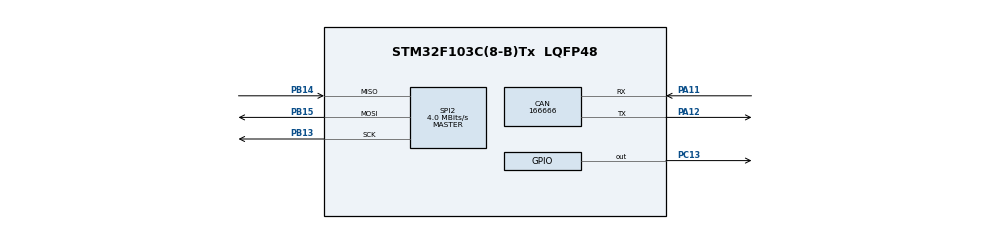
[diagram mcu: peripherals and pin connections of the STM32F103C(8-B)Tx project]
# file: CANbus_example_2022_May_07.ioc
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CAN.CalculateBaudRate=166666
CAN.CalculateTimeBit=6000
CAN.CalculateTimeQuantum=2000.0
Mcu.Family=STM32F1
Mcu.Name=STM32F103C(8-B)Tx
Mcu.Package=LQFP48
NVIC.PriorityGroup=NVIC_PRIORITYGROUP_4
PA11.Mode=CAN_Activate
PA11.Signal=CAN_RX
PA12.Mode=CAN_Activate
PA12.Signal=CAN_TX
PA13.Mode=Serial_Wire
PA13.Signal=SYS_JTMS-SWDIO
PA14.Mode=Serial_Wire
PA14.Signal=SYS_JTCK-SWCLK
PB13.Mode=Full_Duplex_Master
PB13.Signal=SPI2_SCK
PB14.Mode=Full_Duplex_Master
PB14.Signal=SPI2_MISO
PB15.Mode=Full_Duplex_Master
PB15.Signal=SPI2_MOSI
PC13-TAMPER-RTC.Signal=GPIO_Output
ProjectManager.HeapSize=0x200
ProjectManager.StackSize=0x400
ProjectManager.TargetToolchain=STM32CubeIDE
RCC.APB1Freq_Value=8000000
RCC.APB2Freq_Value=8000000
SPI2.CalculateBaudRate=4.0 MBits/s
SPI2.Direction=SPI_DIRECTION_2LINES
SPI2.Mode=SPI_MODE_MASTER
SPI2.VirtualType=VM_MASTER
board=custom

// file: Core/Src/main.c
/* USER CODE BEGIN Header */
/**
  ******************************************************************************
  * @file           : main.c
  * @brief          : Main program body
  ******************************************************************************
  * @attention
  *
  * Copyright (c) 2022 STMicroelectronics.
  * All rights reserved.
  *
  * This software is licensed under terms that can be found in the LICENSE file
  * in the root directory of this software component.
  * If no LICENSE file comes with this software, it is provided AS-IS.
  *
  ******************************************************************************
  */
/* USER CODE END Header */
#include "main.h"

/* USER CODE BEGIN Includes */
#include "BLINKY_bluepill.h"
#include "CANbus_functions.h"

/* USER CODE END Includes */

 CAN_HandleTypeDef hcan;

SPI_HandleTypeDef hspi2;

void SystemClock_Config(void);
static void MX_GPIO_Init(void);
static void MX_CAN_Init(void);
static void MX_SPI2_Init(void);

int main(void)
{
  /* USER CODE BEGIN 1 */
	Brightside_CAN_MessageSeries* pSeries;
  /* USER CODE END 1 */

  /* MCU Configuration--------------------------------------------------------*/

  /* Reset of all peripherals, Initializes the Flash interface and the Systick. */
  HAL_Init();

  /* Configure the system clock */
  SystemClock_Config();

  /* Initialize all configured peripherals */
  MX_GPIO_Init();
  MX_CAN_Init();
  MX_SPI2_Init();
  /* USER CODE BEGIN 2 */

  pSeries = CAN_initStructsAndStuff(&hcan);
  /* USER CODE END 2 */

  /* Infinite loop */
  /* USER CODE BEGIN WHILE */
  while (1)
  {
	  BLINKY_bluepill(100, 400);
	  CAN_main(pSeries);
    /* USER CODE END WHILE */

  }
}

void SystemClock_Config(void)
{
  RCC_OscInitTypeDef RCC_OscInitStruct = {0};
  RCC_ClkInitTypeDef RCC_ClkInitStruct = {0};

  /** Initializes the RCC Oscillators according to the specified parameters
  * in the RCC_OscInitTypeDef structure.
  */
  RCC_OscInitStruct.OscillatorType = RCC_OSCILLATORTYPE_HSI;
  RCC_OscInitStruct.HSIState = RCC_HSI_ON;
  RCC_OscInitStruct.HSICalibrationValue = RCC_HSICALIBRATION_DEFAULT;
  RCC_OscInitStruct.PLL.PLLState = RCC_PLL_NONE;
  if (HAL_RCC_OscConfig(&RCC_OscInitStruct) != HAL_OK)
  {
    Error_Handler();
  }

  /** Initializes the CPU, AHB and APB buses clocks
  */
  RCC_ClkInitStruct.ClockType = RCC_CLOCKTYPE_HCLK|RCC_CLOCKTYPE_SYSCLK
                              |RCC_CLOCKTYPE_PCLK1|RCC_CLOCKTYPE_PCLK2;
  RCC_ClkInitStruct.SYSCLKSource = RCC_SYSCLKSOURCE_HSI;
  RCC_ClkInitStruct.AHBCLKDivider = RCC_SYSCLK_DIV1;
  RCC_ClkInitStruct.APB1CLKDivider = RCC_HCLK_DIV1;
  RCC_ClkInitStruct.APB2CLKDivider = RCC_HCLK_DIV1;

  if (HAL_RCC_ClockConfig(&RCC_ClkInitStruct, FLASH_LATENCY_0) != HAL_OK)
  {
    Error_Handler();
  }
}

static void MX_CAN_Init(void)
{

  hcan.Instance = CAN1;
  hcan.Init.Prescaler = 16;
  hcan.Init.Mode = CAN_MODE_NORMAL;
  hcan.Init.SyncJumpWidth = CAN_SJW_1TQ;
  hcan.Init.TimeSeg1 = CAN_BS1_1TQ;
  hcan.Init.TimeSeg2 = CAN_BS2_1TQ;
  hcan.Init.TimeTriggeredMode = DISABLE;
  hcan.Init.AutoBusOff = DISABLE;
  hcan.Init.AutoWakeUp = DISABLE;
  hcan.Init.AutoRetransmission = DISABLE;
  hcan.Init.ReceiveFifoLocked = DISABLE;
  hcan.Init.TransmitFifoPriority = DISABLE;
  if (HAL_CAN_Init(&hcan) != HAL_OK)
  {
    Error_Handler();
  }

}

static void MX_SPI2_Init(void)
{

  /* SPI2 parameter configuration*/
  hspi2.Instance = SPI2;
  hspi2.Init.Mode = SPI_MODE_MASTER;
  hspi2.Init.Direction = SPI_DIRECTION_2LINES;
  hspi2.Init.DataSize = SPI_DATASIZE_8BIT;
  hspi2.Init.CLKPolarity = SPI_POLARITY_LOW;
  hspi2.Init.CLKPhase = SPI_PHASE_1EDGE;
  hspi2.Init.NSS = SPI_NSS_SOFT;
  hspi2.Init.BaudRatePrescaler = SPI_BAUDRATEPRESCALER_2;
  hspi2.Init.FirstBit = SPI_FIRSTBIT_MSB;
  hspi2.Init.TIMode = SPI_TIMODE_DISABLE;
  hspi2.Init.CRCCalculation = SPI_CRCCALCULATION_DISABLE;
  hspi2.Init.CRCPolynomial = 10;
  if (HAL_SPI_Init(&hspi2) != HAL_OK)
  {
    Error_Handler();
  }

}

static void MX_GPIO_Init(void)
{
  GPIO_InitTypeDef GPIO_InitStruct = {0};

  /* GPIO Ports Clock Enable */
  __HAL_RCC_GPIOC_CLK_ENABLE();
  __HAL_RCC_GPIOB_CLK_ENABLE();
  __HAL_RCC_GPIOA_CLK_ENABLE();

  /*Configure GPIO pin Output Level */
  HAL_GPIO_WritePin(GPIOC, GPIO_PIN_13, GPIO_PIN_RESET);

  /*Configure GPIO pin : PC13 */
  GPIO_InitStruct.Pin = GPIO_PIN_13;
  GPIO_InitStruct.Mode = GPIO_MODE_OUTPUT_PP;
  GPIO_InitStruct.Pull = GPIO_NOPULL;
  GPIO_InitStruct.Speed = GPIO_SPEED_FREQ_LOW;
  HAL_GPIO_Init(GPIOC, &GPIO_InitStruct);

}

void Error_Handler(void)
{
  __disable_irq();
  while (1)
  {
  }
}
